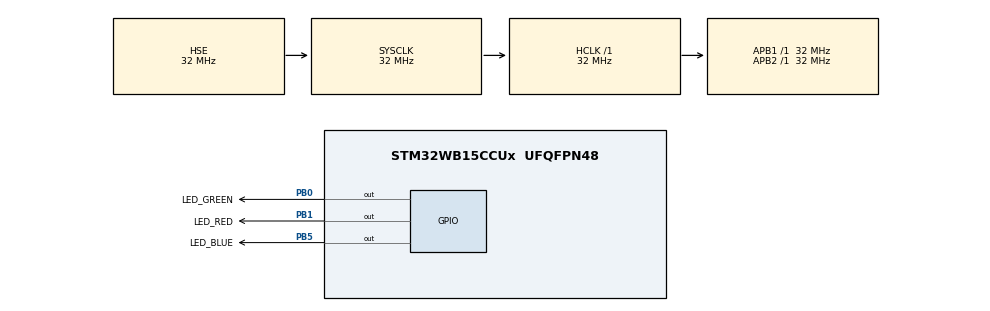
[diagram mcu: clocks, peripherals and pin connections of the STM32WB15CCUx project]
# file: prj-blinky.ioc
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Mcu.Family=STM32WB
Mcu.Name=STM32WB15CCUx
Mcu.Package=UFQFPN48
NVIC.PriorityGroup=NVIC_PRIORITYGROUP_4
OSC_IN.Mode=HSE-External-Oscillator
OSC_IN.Signal=RCC_OSC_IN
OSC_OUT.Mode=HSE-External-Oscillator
OSC_OUT.Signal=RCC_OSC_OUT
PA13.Mode=Serial_Wire
PA13.Signal=SYS_JTMS-SWDIO
PA14.Mode=Serial_Wire
PA14.Signal=SYS_JTCK-SWCLK
PB0.GPIO_Label=LED_GREEN
PB0.Signal=GPIO_Output
PB1.GPIO_Label=LED_RED
PB1.Signal=GPIO_Output
PB5.GPIO_Label=LED_BLUE
PB5.Signal=GPIO_Output
PC14-OSC32_IN.Mode=LSE-External-Oscillator
PC14-OSC32_IN.Signal=RCC_OSC32_IN
PC15-OSC32_OUT.Mode=LSE-External-Oscillator
PC15-OSC32_OUT.Signal=RCC_OSC32_OUT
ProjectManager.HeapSize=0x200
ProjectManager.StackSize=0x400
ProjectManager.TargetToolchain=CMake
RCC.AHBFreq_Value=32000000
RCC.APB1Freq_Value=32000000
RCC.APB1TimFreq_Value=32000000
RCC.APB2Freq_Value=32000000
RCC.APB2TimFreq_Value=32000000
RCC.APB3Freq_Value=16000000
RCC.CortexFreq_Value=32000000
RCC.HCLKFreq_Value=32000000
RCC.HSE_VALUE=32000000
RCC.HSI_VALUE=16000000
RCC.PLLSourceVirtual=RCC_PLLSOURCE_HSI
RCC.SMPSCLockSelectionVirtual=RCC_SMPSCLKSOURCE_HSE
RCC.SMPSDivider=4
RCC.SYSCLKFreq_VALUE=32000000
RCC.SYSCLKSource=RCC_SYSCLKSOURCE_HSE
RCC.VCOOutputFreq_Value=128000000
VP_MEMORYMAP_VS_MEMORYMAP.Mode=CurAppReg
board=custom

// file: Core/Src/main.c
/* USER CODE BEGIN Header */
/**
  ******************************************************************************
  * @file           : main.c
  * @brief          : Main program body
  ******************************************************************************
  * @attention
  *
  * Copyright (c) 2024 STMicroelectronics.
  * All rights reserved.
  *
  * This software is licensed under terms that can be found in the LICENSE file
  * in the root directory of this software component.
  * If no LICENSE file comes with this software, it is provided AS-IS.
  *
  ******************************************************************************
  */
/* USER CODE END Header */
#include "main.h"

void SystemClock_Config(void);
void PeriphCommonClock_Config(void);
static void MX_GPIO_Init(void);

int main(void)
{

  /* MCU Configuration--------------------------------------------------------*/

  /* Reset of all peripherals, Initializes the Flash interface and the Systick. */
  HAL_Init();

  /* Configure the system clock */
  SystemClock_Config();

  /* Configure the peripherals common clocks */
  PeriphCommonClock_Config();

  /* Initialize all configured peripherals */
  MX_GPIO_Init();

  /* Infinite loop */
  while (1)
  {

    /* USER CODE BEGIN 3 */

    HAL_GPIO_TogglePin(LED_BLUE_GPIO_Port, LED_BLUE_Pin);
    HAL_Delay(333);
    HAL_GPIO_TogglePin(LED_GREEN_GPIO_Port, LED_GREEN_Pin);
    HAL_Delay(333);
    HAL_GPIO_TogglePin(LED_RED_GPIO_Port, LED_RED_Pin);
    HAL_Delay(333);
  }
  /* USER CODE END 3 */
}

void SystemClock_Config(void)
{
  RCC_OscInitTypeDef RCC_OscInitStruct = {0};
  RCC_ClkInitTypeDef RCC_ClkInitStruct = {0};

  /** Initializes the RCC Oscillators according to the specified parameters
  * in the RCC_OscInitTypeDef structure.
  */
  RCC_OscInitStruct.OscillatorType = RCC_OSCILLATORTYPE_HSI|RCC_OSCILLATORTYPE_HSE;
  RCC_OscInitStruct.HSEState = RCC_HSE_ON;
  RCC_OscInitStruct.HSIState = RCC_HSI_ON;
  RCC_OscInitStruct.HSICalibrationValue = RCC_HSICALIBRATION_DEFAULT;
  RCC_OscInitStruct.PLL.PLLState = RCC_PLL_NONE;
  if (HAL_RCC_OscConfig(&RCC_OscInitStruct) != HAL_OK)
  {
    Error_Handler();
  }

  /** Configure the SYSCLKSource, HCLK, PCLK1 and PCLK2 clocks dividers
  */
  RCC_ClkInitStruct.ClockType = RCC_CLOCKTYPE_HCLK4|RCC_CLOCKTYPE_HCLK2
                              |RCC_CLOCKTYPE_HCLK|RCC_CLOCKTYPE_SYSCLK
                              |RCC_CLOCKTYPE_PCLK1|RCC_CLOCKTYPE_PCLK2;
  RCC_ClkInitStruct.SYSCLKSource = RCC_SYSCLKSOURCE_HSE;
  RCC_ClkInitStruct.AHBCLKDivider = RCC_SYSCLK_DIV1;
  RCC_ClkInitStruct.APB1CLKDivider = RCC_HCLK_DIV1;
  RCC_ClkInitStruct.APB2CLKDivider = RCC_HCLK_DIV1;
  RCC_ClkInitStruct.AHBCLK2Divider = RCC_SYSCLK_DIV1;
  RCC_ClkInitStruct.AHBCLK4Divider = RCC_SYSCLK_DIV1;

  if (HAL_RCC_ClockConfig(&RCC_ClkInitStruct, FLASH_LATENCY_1) != HAL_OK)
  {
    Error_Handler();
  }
}

void PeriphCommonClock_Config(void)
{
  RCC_PeriphCLKInitTypeDef PeriphClkInitStruct = {0};

  /** Initializes the peripherals clock
  */
  PeriphClkInitStruct.PeriphClockSelection = RCC_PERIPHCLK_SMPS;
  PeriphClkInitStruct.SmpsClockSelection = RCC_SMPSCLKSOURCE_HSE;
  PeriphClkInitStruct.SmpsDivSelection = RCC_SMPSCLKDIV_RANGE1;

  if (HAL_RCCEx_PeriphCLKConfig(&PeriphClkInitStruct) != HAL_OK)
  {
    Error_Handler();
  }
}

static void MX_GPIO_Init(void)
{
  GPIO_InitTypeDef GPIO_InitStruct = {0};

  /* GPIO Ports Clock Enable */
  __HAL_RCC_GPIOC_CLK_ENABLE();
  __HAL_RCC_GPIOB_CLK_ENABLE();
  __HAL_RCC_GPIOA_CLK_ENABLE();

  /*Configure GPIO pin Output Level */
  HAL_GPIO_WritePin(GPIOB, LED_GREEN_Pin|LED_RED_Pin|LED_BLUE_Pin, GPIO_PIN_RESET);

  /*Configure GPIO pins : LED_GREEN_Pin LED_RED_Pin LED_BLUE_Pin */
  GPIO_InitStruct.Pin = LED_GREEN_Pin|LED_RED_Pin|LED_BLUE_Pin;
  GPIO_InitStruct.Mode = GPIO_MODE_OUTPUT_PP;
  GPIO_InitStruct.Pull = GPIO_NOPULL;
  GPIO_InitStruct.Speed = GPIO_SPEED_FREQ_LOW;
  HAL_GPIO_Init(GPIOB, &GPIO_InitStruct);

}

void Error_Handler(void)
{
  __disable_irq();
  while (1)
  {
  }
}
